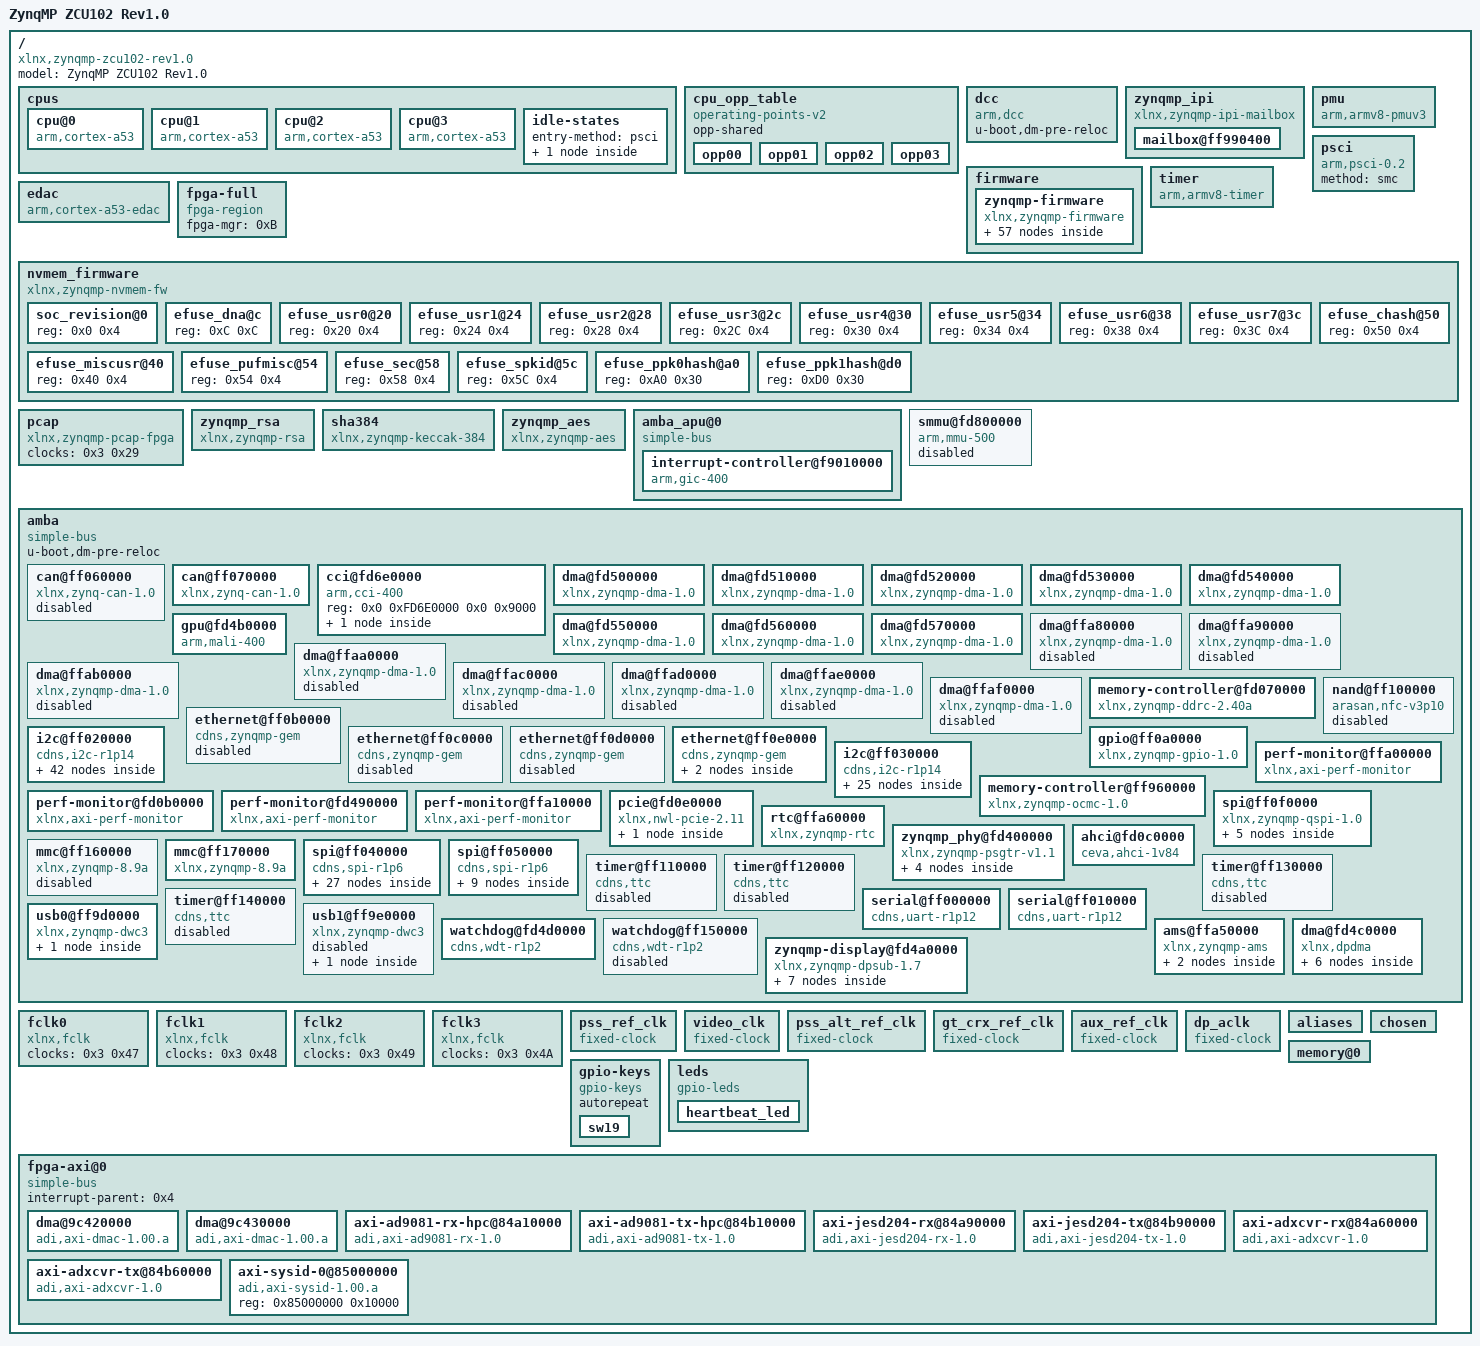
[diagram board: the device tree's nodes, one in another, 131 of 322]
/dts-v1/;
// version: 17
// last_comp_version: 16
// boot_cpuid_phys: 0x0

/ {
    compatible = "xlnx,zynqmp-zcu102-rev1.0", "xlnx,zynqmp-zcu102", "xlnx,zynqmp";
    #address-cells = <0x2>;
    #size-cells = <0x2>;
    model = "ZynqMP ZCU102 Rev1.0";
    cpus {
        #address-cells = <0x1>;
        #size-cells = <0x0>;
        cpu@0 {
            compatible = "arm,cortex-a53", "arm,armv8";
            device_type = "cpu";
            enable-method = "psci";
            operating-points-v2 = <0x1>;
            reg = <0x0>;
            cpu-idle-states = <0x2>;
            clocks = <0x3 0xA>;
        };
        cpu@1 {
            compatible = "arm,cortex-a53", "arm,armv8";
            device_type = "cpu";
            enable-method = "psci";
            reg = <0x1>;
            operating-points-v2 = <0x1>;
            cpu-idle-states = <0x2>;
        };
        cpu@2 {
            compatible = "arm,cortex-a53", "arm,armv8";
            device_type = "cpu";
            enable-method = "psci";
            reg = <0x2>;
            operating-points-v2 = <0x1>;
            cpu-idle-states = <0x2>;
        };
        cpu@3 {
            compatible = "arm,cortex-a53", "arm,armv8";
            device_type = "cpu";
            enable-method = "psci";
            reg = <0x3>;
            operating-points-v2 = <0x1>;
            cpu-idle-states = <0x2>;
        };
        idle-states {
            entry-method = "psci";
            cpu-sleep-0 {
                compatible = "arm,idle-state";
                arm,psci-suspend-param = <0x40000000>;
                local-timer-stop;
                entry-latency-us = <0x12C>;
                exit-latency-us = <0x258>;
                min-residency-us = <0x2710>;
                phandle = <0x2>;
            };
        };
    };
    cpu_opp_table {
        compatible = "operating-points-v2";
        opp-shared;
        phandle = <0x1>;
        opp00 {
            opp-hz = <0x0 0x47868BF4>;
            opp-microvolt = <0xF4240>;
            clock-latency-ns = <0x7A120>;
        };
        opp01 {
            opp-hz = <0x0 0x23C345FA>;
            opp-microvolt = <0xF4240>;
            clock-latency-ns = <0x7A120>;
        };
        opp02 {
            opp-hz = <0x0 0x17D783FC>;
            opp-microvolt = <0xF4240>;
            clock-latency-ns = <0x7A120>;
        };
        opp03 {
            opp-hz = <0x0 0x11E1A2FD>;
            opp-microvolt = <0xF4240>;
            clock-latency-ns = <0x7A120>;
        };
    };
    dcc {
        compatible = "arm,dcc";
        status = "okay";
        u-boot,dm-pre-reloc;
    };
    zynqmp_ipi {
        compatible = "xlnx,zynqmp-ipi-mailbox";
        interrupt-parent = <0x4>;
        interrupts = <0x0 0x23 0x4>;
        xlnx,ipi-id = <0x0>;
        #address-cells = <0x2>;
        #size-cells = <0x2>;
        ranges;
        mailbox@ff990400 {
            reg = <0x0 0xFF9905C0 0x0 0x20 0x0 0xFF9905E0 0x0 0x20 0x0 0xFF990E80 0x0 0x20 0x0 0xFF990EA0 0x0 0x20>;
            reg-names = "local_request_region", "local_response_region", "remote_request_region", "remote_response_region";
            #mbox-cells = <0x1>;
            xlnx,ipi-id = <0x4>;
            phandle = <0x5>;
        };
    };
    pmu {
        compatible = "arm,armv8-pmuv3";
        interrupt-parent = <0x4>;
        interrupts = <0x0 0x8F 0x4 0x0 0x90 0x4 0x0 0x91 0x4 0x0 0x92 0x4>;
    };
    psci {
        compatible = "arm,psci-0.2";
        method = "smc";
    };
    firmware {
        zynqmp-firmware {
            compatible = "xlnx,zynqmp-firmware";
            method = "smc";
            #power-domain-cells = <0x1>;
            u-boot,dm-pre-reloc;
            phandle = <0xC>;
            zynqmp-power {
                compatible = "xlnx,zynqmp-power";
                interrupt-parent = <0x4>;
                interrupts = <0x0 0x23 0x4>;
                mboxes = <0x5 0x0 0x5 0x1>;
                mbox-names = "tx", "rx";
            };
            reset-controller {
                compatible = "xlnx,zynqmp-reset";
                #reset-cells = <0x1>;
                phandle = <0x1A>;
            };
            pinctrl {
                compatible = "xlnx,zynqmp-pinctrl";
                status = "okay";
                i2c0-default {
                    phandle = <0x12>;
                    mux {
                        groups = "i2c0_3_grp";
                        function = "i2c0";
                    };
                    conf {
                        groups = "i2c0_3_grp";
                        bias-pull-up;
                        slew-rate = <0x1>;
                        io-standard = <0x1>;
                    };
                };
                i2c0-gpio {
                    phandle = <0x13>;
                    mux {
                        groups = "gpio0_14_grp", "gpio0_15_grp";
                        function = "gpio0";
                    };
                    conf {
                        groups = "gpio0_14_grp", "gpio0_15_grp";
                        slew-rate = <0x1>;
                        io-standard = <0x1>;
                    };
                };
                i2c1-default {
                    phandle = <0x15>;
                    mux {
                        groups = "i2c1_4_grp";
                        function = "i2c1";
                    };
                    conf {
                        groups = "i2c1_4_grp";
                        bias-pull-up;
                        slew-rate = <0x1>;
                        io-standard = <0x1>;
                    };
                };
                i2c1-gpio {
                    phandle = <0x16>;
                    mux {
                        groups = "gpio0_16_grp", "gpio0_17_grp";
                        function = "gpio0";
                    };
                    conf {
                        groups = "gpio0_16_grp", "gpio0_17_grp";
                        slew-rate = <0x1>;
                        io-standard = <0x1>;
                    };
                };
                uart0-default {
                    phandle = <0x28>;
                    mux {
                        groups = "uart0_4_grp";
                        function = "uart0";
                    };
                    conf {
                        groups = "uart0_4_grp";
                        slew-rate = <0x1>;
                        io-standard = <0x1>;
                    };
                    conf-rx {
                        pins = "MIO18";
                        bias-high-impedance;
                    };
                    conf-tx {
                        pins = "MIO19";
                        bias-disable;
                    };
                };
                uart1-default {
                    phandle = <0x29>;
                    mux {
                        groups = "uart1_5_grp";
                        function = "uart1";
                    };
                    conf {
                        groups = "uart1_5_grp";
                        slew-rate = <0x1>;
                        io-standard = <0x1>;
                    };
                    conf-rx {
                        pins = "MIO21";
                        bias-high-impedance;
                    };
                    conf-tx {
                        pins = "MIO20";
                        bias-disable;
                    };
                };
                usb0-default {
                    phandle = <0x2A>;
                    mux {
                        groups = "usb0_0_grp";
                        function = "usb0";
                    };
                    conf {
                        groups = "usb0_0_grp";
                        slew-rate = <0x1>;
                        io-standard = <0x1>;
                    };
                    conf-rx {
                        pins = "MIO52", "MIO53", "MIO55";
                        bias-high-impedance;
                    };
                    conf-tx {
                        pins = "MIO54", "MIO56", "MIO57", "MIO58", "MIO59", "MIO60", "MIO61", "MIO62", "MIO63";
                        bias-disable;
                    };
                };
                gem3-default {
                    phandle = <0x10>;
                    mux {
                        function = "ethernet3";
                        groups = "ethernet3_0_grp";
                    };
                    conf {
                        groups = "ethernet3_0_grp";
                        slew-rate = <0x1>;
                        io-standard = <0x1>;
                    };
                    conf-rx {
                        pins = "MIO70", "MIO71", "MIO72", "MIO73", "MIO74", "MIO75";
                        bias-high-impedance;
                        low-power-disable;
                    };
                    conf-tx {
                        pins = "MIO64", "MIO65", "MIO66", "MIO67", "MIO68", "MIO69";
                        bias-disable;
                        low-power-enable;
                    };
                    mux-mdio {
                        function = "mdio3";
                        groups = "mdio3_0_grp";
                    };
                    conf-mdio {
                        groups = "mdio3_0_grp";
                        slew-rate = <0x1>;
                        io-standard = <0x1>;
                        bias-disable;
                    };
                };
                can1-default {
                    phandle = <0xD>;
                    mux {
                        function = "can1";
                        groups = "can1_6_grp";
                    };
                    conf {
                        groups = "can1_6_grp";
                        slew-rate = <0x1>;
                        io-standard = <0x1>;
                    };
                    conf-rx {
                        pins = "MIO25";
                        bias-high-impedance;
                    };
                    conf-tx {
                        pins = "MIO24";
                        bias-disable;
                    };
                };
                sdhci1-default {
                    phandle = <0x1C>;
                    mux {
                        groups = "sdio1_0_grp";
                        function = "sdio1";
                    };
                    conf {
                        groups = "sdio1_0_grp";
                        slew-rate = <0x1>;
                        io-standard = <0x1>;
                        bias-disable;
                    };
                    mux-cd {
                        groups = "sdio1_cd_0_grp";
                        function = "sdio1_cd";
                    };
                    conf-cd {
                        groups = "sdio1_cd_0_grp";
                        bias-high-impedance;
                        bias-pull-up;
                        slew-rate = <0x1>;
                        io-standard = <0x1>;
                    };
                    mux-wp {
                        groups = "sdio1_wp_0_grp";
                        function = "sdio1_wp";
                    };
                    conf-wp {
                        groups = "sdio1_wp_0_grp";
                        bias-high-impedance;
                        bias-pull-up;
                        slew-rate = <0x1>;
                        io-standard = <0x1>;
                    };
                };
                gpio-default {
                    phandle = <0x11>;
                    mux-sw {
                        function = "gpio0";
                        groups = "gpio0_22_grp", "gpio0_23_grp";
                    };
                    conf-sw {
                        groups = "gpio0_22_grp", "gpio0_23_grp";
                        slew-rate = <0x1>;
                        io-standard = <0x1>;
                    };
                    mux-msp {
                        function = "gpio0";
                        groups = "gpio0_13_grp", "gpio0_38_grp";
                    };
                    conf-msp {
                        groups = "gpio0_13_grp", "gpio0_38_grp";
                        slew-rate = <0x1>;
                        io-standard = <0x1>;
                    };
                    conf-pull-up {
                        pins = "MIO22", "MIO23";
                        bias-pull-up;
                    };
                    conf-pull-none {
                        pins = "MIO13", "MIO38";
                        bias-disable;
                    };
                };
            };
            clock-controller {
                u-boot,dm-pre-reloc;
                #clock-cells = <0x1>;
                compatible = "xlnx,zynqmp-clk";
                clocks = <0x6 0x7 0x8 0x9 0xA>;
                clock-names = "pss_ref_clk", "video_clk", "pss_alt_ref_clk", "aux_ref_clk", "gt_crx_ref_clk";
                phandle = <0x3>;
            };
        };
    };
    timer {
        compatible = "arm,armv8-timer";
        interrupt-parent = <0x4>;
        interrupts = <0x1 0xD 0xF08 0x1 0xE 0xF08 0x1 0xB 0xF08 0x1 0xA 0xF08>;
    };
    edac {
        compatible = "arm,cortex-a53-edac";
    };
    fpga-full {
        compatible = "fpga-region";
        fpga-mgr = <0xB>;
        #address-cells = <0x2>;
        #size-cells = <0x2>;
    };
    nvmem_firmware {
        compatible = "xlnx,zynqmp-nvmem-fw";
        #address-cells = <0x1>;
        #size-cells = <0x1>;
        soc_revision@0 {
            reg = <0x0 0x4>;
            phandle = <0x19>;
        };
        efuse_dna@c {
            reg = <0xC 0xC>;
        };
        efuse_usr0@20 {
            reg = <0x20 0x4>;
        };
        efuse_usr1@24 {
            reg = <0x24 0x4>;
        };
        efuse_usr2@28 {
            reg = <0x28 0x4>;
        };
        efuse_usr3@2c {
            reg = <0x2C 0x4>;
        };
        efuse_usr4@30 {
            reg = <0x30 0x4>;
        };
        efuse_usr5@34 {
            reg = <0x34 0x4>;
        };
        efuse_usr6@38 {
            reg = <0x38 0x4>;
        };
        efuse_usr7@3c {
            reg = <0x3C 0x4>;
        };
        efuse_miscusr@40 {
            reg = <0x40 0x4>;
        };
        efuse_chash@50 {
            reg = <0x50 0x4>;
        };
        efuse_pufmisc@54 {
            reg = <0x54 0x4>;
        };
        efuse_sec@58 {
            reg = <0x58 0x4>;
        };
        efuse_spkid@5c {
            reg = <0x5C 0x4>;
        };
        efuse_ppk0hash@a0 {
            reg = <0xA0 0x30>;
        };
        efuse_ppk1hash@d0 {
            reg = <0xD0 0x30>;
        };
    };
    pcap {
        compatible = "xlnx,zynqmp-pcap-fpga";
        clock-names = "ref_clk";
        clocks = <0x3 0x29>;
        phandle = <0xB>;
    };
    zynqmp_rsa {
        compatible = "xlnx,zynqmp-rsa";
    };
    sha384 {
        compatible = "xlnx,zynqmp-keccak-384";
    };
    zynqmp_aes {
        compatible = "xlnx,zynqmp-aes";
    };
    amba_apu@0 {
        compatible = "simple-bus";
        #address-cells = <0x2>;
        #size-cells = <0x1>;
        ranges = <0x0 0x0 0x0 0x0 0xFFFFFFFF>;
        interrupt-controller@f9010000 {
            compatible = "arm,gic-400", "arm,cortex-a15-gic";
            #interrupt-cells = <0x3>;
            reg = <0x0 0xF9010000 0x10000 0x0 0xF9020000 0x20000 0x0 0xF9040000 0x20000 0x0 0xF9060000 0x20000>;
            interrupt-controller;
            interrupt-parent = <0x4>;
            interrupts = <0x1 0x9 0xF04>;
            phandle = <0x4>;
        };
    };
    smmu@fd800000 {
        compatible = "arm,mmu-500";
        reg = <0x0 0xFD800000 0x0 0x20000>;
        #iommu-cells = <0x1>;
        status = "disabled";
        #global-interrupts = <0x1>;
        interrupt-parent = <0x4>;
        interrupts = <0x0 0x9B 0x4 0x0 0x9B 0x4 0x0 0x9B 0x4 0x0 0x9B 0x4 0x0 0x9B 0x4 0x0 0x9B 0x4 0x0 0x9B 0x4 0x0 0x9B 0x4 0x0 0x9B 0x4 0x0 0x9B 0x4 0x0 0x9B 0x4 0x0 0x9B 0x4 0x0 0x9B 0x4 0x0 0x9B 0x4 0x0 0x9B 0x4 0x0 0x9B 0x4 0x0 0x9B 0x4>;
        phandle = <0xE>;
    };
    amba {
        compatible = "simple-bus";
        u-boot,dm-pre-reloc;
        #address-cells = <0x2>;
        #size-cells = <0x2>;
        ranges;
        can@ff060000 {
            compatible = "xlnx,zynq-can-1.0";
            status = "disabled";
            clock-names = "can_clk", "pclk";
            reg = <0x0 0xFF060000 0x0 0x1000>;
            interrupts = <0x0 0x17 0x4>;
            interrupt-parent = <0x4>;
            tx-fifo-depth = <0x40>;
            rx-fifo-depth = <0x40>;
            power-domains = <0xC 0x2F>;
            clocks = <0x3 0x3F 0x3 0x1F>;
        };
        can@ff070000 {
            compatible = "xlnx,zynq-can-1.0";
            status = "okay";
            clock-names = "can_clk", "pclk";
            reg = <0x0 0xFF070000 0x0 0x1000>;
            interrupts = <0x0 0x18 0x4>;
            interrupt-parent = <0x4>;
            tx-fifo-depth = <0x40>;
            rx-fifo-depth = <0x40>;
            power-domains = <0xC 0x30>;
            clocks = <0x3 0x40 0x3 0x1F>;
            pinctrl-names = "default";
            pinctrl-0 = <0xD>;
        };
        cci@fd6e0000 {
            compatible = "arm,cci-400";
            reg = <0x0 0xFD6E0000 0x0 0x9000>;
            ranges = <0x0 0x0 0xFD6E0000 0x10000>;
            #address-cells = <0x1>;
            #size-cells = <0x1>;
            pmu@9000 {
                compatible = "arm,cci-400-pmu,r1";
                reg = <0x9000 0x5000>;
                interrupt-parent = <0x4>;
                interrupts = <0x0 0x7B 0x4 0x0 0x7B 0x4 0x0 0x7B 0x4 0x0 0x7B 0x4 0x0 0x7B 0x4>;
            };
        };
        dma@fd500000 {
            status = "okay";
            compatible = "xlnx,zynqmp-dma-1.0";
            reg = <0x0 0xFD500000 0x0 0x1000>;
            interrupt-parent = <0x4>;
            interrupts = <0x0 0x7C 0x4>;
            clock-names = "clk_main", "clk_apb";
            xlnx,bus-width = <0x80>;
            #stream-id-cells = <0x1>;
            iommus = <0xE 0x14E8>;
            power-domains = <0xC 0x2A>;
            clocks = <0x3 0x13 0x3 0x1F>;
        };
        dma@fd510000 {
            status = "okay";
            compatible = "xlnx,zynqmp-dma-1.0";
            reg = <0x0 0xFD510000 0x0 0x1000>;
            interrupt-parent = <0x4>;
            interrupts = <0x0 0x7D 0x4>;
            clock-names = "clk_main", "clk_apb";
            xlnx,bus-width = <0x80>;
            #stream-id-cells = <0x1>;
            iommus = <0xE 0x14E9>;
            power-domains = <0xC 0x2A>;
            clocks = <0x3 0x13 0x3 0x1F>;
        };
        dma@fd520000 {
            status = "okay";
            compatible = "xlnx,zynqmp-dma-1.0";
            reg = <0x0 0xFD520000 0x0 0x1000>;
            interrupt-parent = <0x4>;
            interrupts = <0x0 0x7E 0x4>;
            clock-names = "clk_main", "clk_apb";
            xlnx,bus-width = <0x80>;
            #stream-id-cells = <0x1>;
            iommus = <0xE 0x14EA>;
            power-domains = <0xC 0x2A>;
            clocks = <0x3 0x13 0x3 0x1F>;
        };
        dma@fd530000 {
            status = "okay";
            compatible = "xlnx,zynqmp-dma-1.0";
            reg = <0x0 0xFD530000 0x0 0x1000>;
            interrupt-parent = <0x4>;
            interrupts = <0x0 0x7F 0x4>;
            clock-names = "clk_main", "clk_apb";
            xlnx,bus-width = <0x80>;
            #stream-id-cells = <0x1>;
            iommus = <0xE 0x14EB>;
            power-domains = <0xC 0x2A>;
            clocks = <0x3 0x13 0x3 0x1F>;
        };
        dma@fd540000 {
            status = "okay";
            compatible = "xlnx,zynqmp-dma-1.0";
            reg = <0x0 0xFD540000 0x0 0x1000>;
            interrupt-parent = <0x4>;
            interrupts = <0x0 0x80 0x4>;
            clock-names = "clk_main", "clk_apb";
            xlnx,bus-width = <0x80>;
            #stream-id-cells = <0x1>;
            iommus = <0xE 0x14EC>;
            power-domains = <0xC 0x2A>;
            clocks = <0x3 0x13 0x3 0x1F>;
        };
        dma@fd550000 {
            status = "okay";
            compatible = "xlnx,zynqmp-dma-1.0";
            reg = <0x0 0xFD550000 0x0 0x1000>;
            interrupt-parent = <0x4>;
            interrupts = <0x0 0x81 0x4>;
            clock-names = "clk_main", "clk_apb";
            xlnx,bus-width = <0x80>;
            #stream-id-cells = <0x1>;
            iommus = <0xE 0x14ED>;
            power-domains = <0xC 0x2A>;
            clocks = <0x3 0x13 0x3 0x1F>;
        };
        dma@fd560000 {
            status = "okay";
            compatible = "xlnx,zynqmp-dma-1.0";
            reg = <0x0 0xFD560000 0x0 0x1000>;
            interrupt-parent = <0x4>;
            interrupts = <0x0 0x82 0x4>;
            clock-names = "clk_main", "clk_apb";
            xlnx,bus-width = <0x80>;
            #stream-id-cells = <0x1>;
            iommus = <0xE 0x14EE>;
            power-domains = <0xC 0x2A>;
            clocks = <0x3 0x13 0x3 0x1F>;
        };
        dma@fd570000 {
            status = "okay";
            compatible = "xlnx,zynqmp-dma-1.0";
            reg = <0x0 0xFD570000 0x0 0x1000>;
            interrupt-parent = <0x4>;
            interrupts = <0x0 0x83 0x4>;
            clock-names = "clk_main", "clk_apb";
            xlnx,bus-width = <0x80>;
            #stream-id-cells = <0x1>;
            iommus = <0xE 0x14EF>;
            power-domains = <0xC 0x2A>;
            clocks = <0x3 0x13 0x3 0x1F>;
        };
        gpu@fd4b0000 {
            status = "okay";
            compatible = "arm,mali-400", "arm,mali-utgard";
            reg = <0x0 0xFD4B0000 0x0 0x10000>;
            interrupt-parent = <0x4>;
            interrupts = <0x0 0x84 0x4 0x0 0x84 0x4 0x0 0x84 0x4 0x0 0x84 0x4 0x0 0x84 0x4 0x0 0x84 0x4>;
            interrupt-names = "IRQGP", "IRQGPMMU", "IRQPP0", "IRQPPMMU0", "IRQPP1", "IRQPPMMU1";
            clock-names = "gpu", "gpu_pp0", "gpu_pp1";
            power-domains = <0xC 0x3A>;
            clocks = <0x3 0x18 0x3 0x19 0x3 0x1A>;
        };
        dma@ffa80000 {
            status = "disabled";
            compatible = "xlnx,zynqmp-dma-1.0";
            reg = <0x0 0xFFA80000 0x0 0x1000>;
            interrupt-parent = <0x4>;
            interrupts = <0x0 0x4D 0x4>;
            clock-names = "clk_main", "clk_apb";
            xlnx,bus-width = <0x40>;
            #stream-id-cells = <0x1>;
            power-domains = <0xC 0x2B>;
            clocks = <0x3 0x44 0x3 0x1F>;
        };
        dma@ffa90000 {
            status = "disabled";
            compatible = "xlnx,zynqmp-dma-1.0";
            reg = <0x0 0xFFA90000 0x0 0x1000>;
            interrupt-parent = <0x4>;
            interrupts = <0x0 0x4E 0x4>;
            clock-names = "clk_main", "clk_apb";
            xlnx,bus-width = <0x40>;
            #stream-id-cells = <0x1>;
            power-domains = <0xC 0x2B>;
            clocks = <0x3 0x44 0x3 0x1F>;
        };
        dma@ffaa0000 {
            status = "disabled";
            compatible = "xlnx,zynqmp-dma-1.0";
            reg = <0x0 0xFFAA0000 0x0 0x1000>;
            interrupt-parent = <0x4>;
            interrupts = <0x0 0x4F 0x4>;
            clock-names = "clk_main", "clk_apb";
            xlnx,bus-width = <0x40>;
            #stream-id-cells = <0x1>;
            power-domains = <0xC 0x2B>;
            clocks = <0x3 0x44 0x3 0x1F>;
        };
        dma@ffab0000 {
            status = "disabled";
            compatible = "xlnx,zynqmp-dma-1.0";
            reg = <0x0 0xFFAB0000 0x0 0x1000>;
            interrupt-parent = <0x4>;
            interrupts = <0x0 0x50 0x4>;
            clock-names = "clk_main", "clk_apb";
            xlnx,bus-width = <0x40>;
            #stream-id-cells = <0x1>;
            power-domains = <0xC 0x2B>;
            clocks = <0x3 0x44 0x3 0x1F>;
        };
        dma@ffac0000 {
            status = "disabled";
            compatible = "xlnx,zynqmp-dma-1.0";
            reg = <0x0 0xFFAC0000 0x0 0x1000>;
            interrupt-parent = <0x4>;
            interrupts = <0x0 0x51 0x4>;
            clock-names = "clk_main", "clk_apb";
            xlnx,bus-width = <0x40>;
            #stream-id-cells = <0x1>;
            power-domains = <0xC 0x2B>;
            clocks = <0x3 0x44 0x3 0x1F>;
        };
        dma@ffad0000 {
            status = "disabled";
            compatible = "xlnx,zynqmp-dma-1.0";
            reg = <0x0 0xFFAD0000 0x0 0x1000>;
            interrupt-parent = <0x4>;
            interrupts = <0x0 0x52 0x4>;
            clock-names = "clk_main", "clk_apb";
            xlnx,bus-width = <0x40>;
            #stream-id-cells = <0x1>;
            power-domains = <0xC 0x2B>;
            clocks = <0x3 0x44 0x3 0x1F>;
        };
        dma@ffae0000 {
            status = "disabled";
            compatible = "xlnx,zynqmp-dma-1.0";
            reg = <0x0 0xFFAE0000 0x0 0x1000>;
            interrupt-parent = <0x4>;
            interrupts = <0x0 0x53 0x4>;
            clock-names = "clk_main", "clk_apb";
            xlnx,bus-width = <0x40>;
            #stream-id-cells = <0x1>;
            power-domains = <0xC 0x2B>;
            clocks = <0x3 0x44 0x3 0x1F>;
        };
        dma@ffaf0000 {
            status = "disabled";
            compatible = "xlnx,zynqmp-dma-1.0";
            reg = <0x0 0xFFAF0000 0x0 0x1000>;
            interrupt-parent = <0x4>;
            interrupts = <0x0 0x54 0x4>;
            clock-names = "clk_main", "clk_apb";
            xlnx,bus-width = <0x40>;
            #stream-id-cells = <0x1>;
            power-domains = <0xC 0x2B>;
            clocks = <0x3 0x44 0x3 0x1F>;
        };
        memory-controller@fd070000 {
            compatible = "xlnx,zynqmp-ddrc-2.40a";
            reg = <0x0 0xFD070000 0x0 0x30000>;
            interrupt-parent = <0x4>;
            interrupts = <0x0 0x70 0x4>;
        };
        nand@ff100000 {
            compatible = "arasan,nfc-v3p10";
            status = "disabled";
            reg = <0x0 0xFF100000 0x0 0x1000>;
            clock-names = "clk_sys", "clk_flash";
            interrupt-parent = <0x4>;
            interrupts = <0x0 0xE 0x4>;
            #address-cells = <0x1>;
            #size-cells = <0x0>;
            #stream-id-cells = <0x1>;
            iommus = <0xE 0x872>;
            power-domains = <0xC 0x2C>;
            clocks = <0x3 0x3C 0x3 0x1F>;
        };
        ethernet@ff0b0000 {
            compatible = "cdns,zynqmp-gem", "cdns,gem";
            status = "disabled";
            interrupt-parent = <0x4>;
            interrupts = <0x0 0x39 0x4 0x0 0x39 0x4>;
            reg = <0x0 0xFF0B0000 0x0 0x1000>;
            clock-names = "pclk", "hclk", "tx_clk", "rx_clk", "tsu_clk";
            #address-cells = <0x1>;
            #size-cells = <0x0>;
            #stream-id-cells = <0x1>;
            iommus = <0xE 0x874>;
            power-domains = <0xC 0x1D>;
            clocks = <0x3 0x1F 0x3 0x68 0x3 0x2D 0x3 0x31 0x3 0x2C>;
        };
        ethernet@ff0c0000 {
            compatible = "cdns,zynqmp-gem", "cdns,gem";
            status = "disabled";
            interrupt-parent = <0x4>;
            interrupts = <0x0 0x3B 0x4 0x0 0x3B 0x4>;
            reg = <0x0 0xFF0C0000 0x0 0x1000>;
            clock-names = "pclk", "hclk", "tx_clk", "rx_clk", "tsu_clk";
            #address-cells = <0x1>;
            #size-cells = <0x0>;
            #stream-id-cells = <0x1>;
            iommus = <0xE 0x875>;
            power-domains = <0xC 0x1E>;
            clocks = <0x3 0x1F 0x3 0x69 0x3 0x2E 0x3 0x32 0x3 0x2C>;
        };
        ethernet@ff0d0000 {
            compatible = "cdns,zynqmp-gem", "cdns,gem";
            status = "disabled";
            interrupt-parent = <0x4>;
            interrupts = <0x0 0x3D 0x4 0x0 0x3D 0x4>;
            reg = <0x0 0xFF0D0000 0x0 0x1000>;
            clock-names = "pclk", "hclk", "tx_clk", "rx_clk", "tsu_clk";
            #address-cells = <0x1>;
            #size-cells = <0x0>;
            #stream-id-cells = <0x1>;
            iommus = <0xE 0x876>;
            power-domains = <0xC 0x1F>;
            clocks = <0x3 0x1F 0x3 0x6A 0x3 0x2F 0x3 0x33 0x3 0x2C>;
        };
        ethernet@ff0e0000 {
            compatible = "cdns,zynqmp-gem", "cdns,gem";
            status = "okay";
            interrupt-parent = <0x4>;
            interrupts = <0x0 0x3F 0x4 0x0 0x3F 0x4>;
            reg = <0x0 0xFF0E0000 0x0 0x1000>;
            clock-names = "pclk", "hclk", "tx_clk", "rx_clk", "tsu_clk";
            #address-cells = <0x1>;
            #size-cells = <0x0>;
            #stream-id-cells = <0x1>;
            iommus = <0xE 0x877>;
            power-domains = <0xC 0x20>;
            clocks = <0x3 0x1F 0x3 0x6B 0x3 0x30 0x3 0x34 0x3 0x2C>;
            phy-handle = <0xF>;
            phy-mode = "rgmii-id";
            pinctrl-names = "default";
            pinctrl-0 = <0x10>;
            ethernet-phy@21 {
                reg = <0x15>;
                ti,rx-internal-delay = <0x8>;
                ti,tx-internal-delay = <0xA>;
                ti,fifo-depth = <0x1>;
                ti,dp83867-rxctrl-strap-quirk;
            };
            ethernet-phy@c {
                reg = <0xC>;
                ti,rx-internal-delay = <0x8>;
                ti,tx-internal-delay = <0xA>;
                ti,fifo-depth = <0x1>;
                ti,dp83867-rxctrl-strap-quirk;
                phandle = <0xF>;
            };
        };
        gpio@ff0a0000 {
            compatible = "xlnx,zynqmp-gpio-1.0";
            status = "okay";
            #gpio-cells = <0x2>;
            interrupt-parent = <0x4>;
            interrupts = <0x0 0x10 0x4>;
            interrupt-controller;
            #interrupt-cells = <0x2>;
            reg = <0x0 0xFF0A0000 0x0 0x1000>;
            gpio-controller;
            power-domains = <0xC 0x2E>;
            clocks = <0x3 0x1F>;
            pinctrl-names = "default";
            pinctrl-0 = <0x11>;
            phandle = <0x14>;
        };
        i2c@ff020000 {
            compatible = "cdns,i2c-r1p14", "cdns,i2c-r1p10";
            status = "okay";
            interrupt-parent = <0x4>;
            interrupts = <0x0 0x11 0x4>;
            reg = <0x0 0xFF020000 0x0 0x1000>;
            #address-cells = <0x1>;
            #size-cells = <0x0>;
            power-domains = <0xC 0x25>;
            clocks = <0x3 0x3D>;
            clock-frequency = <0x61A80>;
            pinctrl-names = "default", "gpio";
            pinctrl-0 = <0x12>;
            pinctrl-1 = <0x13>;
            scl-gpios = <0x14 0xE 0x0>;
            sda-gpios = <0x14 0xF 0x0>;
            gpio@20 {
                compatible = "ti,tca6416";
                reg = <0x20>;
                gpio-controller;
                #gpio-cells = <0x2>;
                gpio-line-names = [50 53 5F 47 54 52 5F 4C 41 4E 5F 53 45 4C 30 00 50 53 5F 47 54 52 5F 4C 41 4E 5F 53 45 4C 31 00 50 53 5F 47 54 52 5F 4C 41 4E 5F 53 45 4C 32 00 50 53 5F 47 54 52 5F 4C 41 4E 5F 53 45 4C 33 00 50 43 49 5F 43 4C 4B 5F 44 49 52 5F 53 45 4C 00 49 49 43 5F 4D 55 58 5F 52 45 53 45 54 5F 42 00 47 45 4D 33 5F 45 58 50 5F 52 45 53 45 54 5F 42 00 00 00 00 00 00 00 00 00 00];
                gtr_sel0 {
                    gpio-hog;
                    gpios = <0x0 0x0>;
                    output-low;
                    line-name = "sel0";
                };
                gtr_sel1 {
                    gpio-hog;
                    gpios = <0x1 0x0>;
                    output-high;
                    line-name = "sel1";
                };
                gtr_sel2 {
                    gpio-hog;
                    gpios = <0x2 0x0>;
                    output-high;
                    line-name = "sel2";
                };
                gtr_sel3 {
                    gpio-hog;
                    gpios = <0x3 0x0>;
                    output-high;
                    line-name = "sel3";
                };
            };
            gpio@21 {
                compatible = "ti,tca6416";
                reg = <0x21>;
                gpio-controller;
                #gpio-cells = <0x2>;
                gpio-line-names = [56 43 43 50 53 50 4C 4C 5F 45 4E 00 4D 47 54 52 41 56 43 43 5F 45 4E 00 4D 47 54 52 41 56 54 54 5F 45 4E 00 56 43 43 50 53 44 44 52 50 4C 4C 5F 45 4E 00 4D 49 4F 32 36 5F 50 4D 55 5F 49 4E 50 55 54 5F 4C 53 00 50 4C 5F 50 4D 42 55 53 5F 41 4C 45 52 54 00 50 53 5F 50 4D 42 55 53 5F 41 4C 45 52 54 00 4D 41 58 49 4D 5F 50 4D 42 55 53 5F 41 4C 45 52 54 00 50 4C 5F 44 44 52 34 5F 56 54 45 52 4D 5F 45 4E 00 50 4C 5F 44 44 52 34 5F 56 50 50 5F 32 56 35 5F 45 4E 00 50 53 5F 44 49 4D 4D 5F 56 44 44 51 5F 54 4F 5F 50 53 56 43 43 4F 5F 4F 4E 00 50 53 5F 44 49 4D 4D 5F 53 55 53 50 45 4E 44 5F 45 4E 00 50 53 5F 44 44 52 34 5F 56 54 45 52 4D 5F 45 4E 00 50 53 5F 44 44 52 34 5F 56 50 50 5F 32 56 35 5F 45 4E 00 00 00];
            };
            i2c-mux@75 {
                compatible = "nxp,pca9544";
                #address-cells = <0x1>;
                #size-cells = <0x0>;
                reg = <0x75>;
                i2c@0 {
                    #address-cells = <0x1>;
                    #size-cells = <0x0>;
                    reg = <0x0>;
                    ina226@40 {
                        compatible = "ti,ina226";
                        reg = <0x40>;
                        shunt-resistor = <0x1388>;
                    };
                    ina226@41 {
                        compatible = "ti,ina226";
                        reg = <0x41>;
                        shunt-resistor = <0x1388>;
                    };
                    ina226@42 {
                        compatible = "ti,ina226";
                        reg = <0x42>;
                        shunt-resistor = <0x1388>;
                    };
                    ina226@43 {
                        compatible = "ti,ina226";
                        reg = <0x43>;
                        shunt-resistor = <0x1388>;
                    };
                    ina226@44 {
                        compatible = "ti,ina226";
                        reg = <0x44>;
                        shunt-resistor = <0x1388>;
                    };
                    ina226@45 {
                        compatible = "ti,ina226";
                        reg = <0x45>;
                        shunt-resistor = <0x1388>;
                    };
                    ina226@46 {
                        compatible = "ti,ina226";
                        reg = <0x46>;
                        shunt-resistor = <0x1388>;
                    };
                    ina226@47 {
                        compatible = "ti,ina226";
                        reg = <0x47>;
                        shunt-resistor = <0x1388>;
                    };
                    ina226@4a {
                        compatible = "ti,ina226";
                        reg = <0x4A>;
                        shunt-resistor = <0x1388>;
                    };
                    ina226@4b {
                        compatible = "ti,ina226";
                        reg = <0x4B>;
                        shunt-resistor = <0x1388>;
                    };
                };
                i2c@1 {
                    #address-cells = <0x1>;
                    #size-cells = <0x0>;
                    reg = <0x1>;
                    ina226@40 {
                        compatible = "ti,ina226";
                        reg = <0x40>;
                        shunt-resistor = <0x7D0>;
                    };
                    ina226@41 {
                        compatible = "ti,ina226";
                        reg = <0x41>;
                        shunt-resistor = <0x1388>;
                    };
                    ina226@42 {
                        compatible = "ti,ina226";
                        reg = <0x42>;
                        shunt-resistor = <0x1388>;
                    };
                    ina226@43 {
                        compatible = "ti,ina226";
                        reg = <0x43>;
                        shunt-resistor = <0x1388>;
                    };
                    ina226@44 {
                        compatible = "ti,ina226";
                        reg = <0x44>;
                        shunt-resistor = <0x1388>;
                    };
                    ina226@45 {
                        compatible = "ti,ina226";
                        reg = <0x45>;
                        shunt-resistor = <0x1388>;
                    };
                    ina226@46 {
                        compatible = "ti,ina226";
                        reg = <0x46>;
                        shunt-resistor = <0x1388>;
                    };
                    ina226@47 {
                        compatible = "ti,ina226";
                        reg = <0x47>;
                        shunt-resistor = <0x1388>;
                    };
                };
                i2c@2 {
                    #address-cells = <0x1>;
                    #size-cells = <0x0>;
                    reg = <0x2>;
                    max15301@a {
                        compatible = "maxim,max15301";
                        reg = <0xA>;
                    };
                    max15303@b {
                        compatible = "maxim,max15303";
                        reg = <0xB>;
                    };
                    max15303@10 {
                        compatible = "maxim,max15303";
                        reg = <0x10>;
                    };
                    max15301@13 {
                        compatible = "maxim,max15301";
                        reg = <0x13>;
                    };
                    max15303@14 {
                        compatible = "maxim,max15303";
                        reg = <0x14>;
                    };
                    max15303@15 {
                        compatible = "maxim,max15303";
                        reg = <0x15>;
                    };
                    max15303@16 {
                        compatible = "maxim,max15303";
                        reg = <0x16>;
                    };
                    max15303@17 {
                        compatible = "maxim,max15303";
                        reg = <0x17>;
                    };
                    max15301@18 {
                        compatible = "maxim,max15301";
                        reg = <0x18>;
                    };
                    max15303@1a {
                        compatible = "maxim,max15303";
                        reg = <0x1A>;
                    };
                    max15303@1d {
                        compatible = "maxim,max15303";
                        reg = <0x1D>;
                    };
                    max20751@72 {
                        compatible = "maxim,max20751";
                        reg = <0x72>;
                    };
                    max20751@73 {
                        compatible = "maxim,max20751";
                        reg = <0x73>;
                    };
                    max15303@1b {
                        compatible = "maxim,max15303";
                        reg = <0x1B>;
                    };
                };
            };
        };
        i2c@ff030000 {
            compatible = "cdns,i2c-r1p14", "cdns,i2c-r1p10";
            status = "okay";
            interrupt-parent = <0x4>;
            interrupts = <0x0 0x12 0x4>;
            reg = <0x0 0xFF030000 0x0 0x1000>;
            #address-cells = <0x1>;
            #size-cells = <0x0>;
            power-domains = <0xC 0x26>;
            clocks = <0x3 0x3E>;
            clock-frequency = <0x61A80>;
            pinctrl-names = "default", "gpio";
            pinctrl-0 = <0x15>;
            pinctrl-1 = <0x16>;
            scl-gpios = <0x14 0x10 0x0>;
            sda-gpios = <0x14 0x11 0x0>;
            i2c-mux@74 {
                compatible = "nxp,pca9548";
                #address-cells = <0x1>;
                #size-cells = <0x0>;
                reg = <0x74>;
                i2c@0 {
                    #address-cells = <0x1>;
                    #size-cells = <0x0>;
                    reg = <0x0>;
                    eeprom@54 {
                        compatible = "atmel,24c08";
                        reg = <0x54>;
                        #address-cells = <0x1>;
                        #size-cells = <0x1>;
                        board-sn@0 {
                            reg = <0x0 0x14>;
                        };
                        eth-mac@20 {
                            reg = <0x20 0x6>;
                        };
                        board-name@d0 {
                            reg = <0xD0 0x6>;
                        };
                        board-revision@e0 {
                            reg = <0xE0 0x3>;
                        };
                    };
                };
                i2c@1 {
                    #address-cells = <0x1>;
                    #size-cells = <0x0>;
                    reg = <0x1>;
                    clock-generator@36 {
                        compatible = "silabs,si5341";
                        reg = <0x36>;
                    };
                };
                i2c@2 {
                    #address-cells = <0x1>;
                    #size-cells = <0x0>;
                    reg = <0x2>;
                    clock-generator@5d {
                        #clock-cells = <0x0>;
                        compatible = "silabs,si570";
                        reg = <0x5D>;
                        temperature-stability = <0x32>;
                        factory-fout = <0x11E1A300>;
                        clock-frequency = <0x11E1A300>;
                        clock-output-names = "si570_user";
                    };
                };
                i2c@3 {
                    #address-cells = <0x1>;
                    #size-cells = <0x0>;
                    reg = <0x3>;
                    clock-generator@5d {
                        #clock-cells = <0x0>;
                        compatible = "silabs,si570";
                        reg = <0x5D>;
                        temperature-stability = <0x32>;
                        factory-fout = <0x9502F90>;
                        clock-frequency = <0x8D9EE20>;
                        clock-output-names = "si570_mgt";
                    };
                };
                i2c@4 {
                    #address-cells = <0x1>;
                    #size-cells = <0x0>;
                    reg = <0x4>;
                    clock-generator@69 {
                        compatible = "silabs,si5328";
                        reg = <0x69>;
                    };
                };
            };
            i2c-mux@75 {
                compatible = "nxp,pca9548";
                #address-cells = <0x1>;
                #size-cells = <0x0>;
                reg = <0x75>;
                i2c@0 {
                    #address-cells = <0x1>;
                    #size-cells = <0x0>;
                    reg = <0x0>;
                    eeprom@50 {
                        compatible = "at24,24c02";
                        reg = <0x50>;
                    };
                };
                i2c@1 {
                    #address-cells = <0x1>;
                    #size-cells = <0x0>;
                    reg = <0x1>;
                };
                i2c@2 {
                    #address-cells = <0x1>;
                    #size-cells = <0x0>;
                    reg = <0x2>;
                };
                i2c@3 {
                    #address-cells = <0x1>;
                    #size-cells = <0x0>;
                    reg = <0x3>;
                };
                i2c@4 {
                    #address-cells = <0x1>;
                    #size-cells = <0x0>;
                    reg = <0x4>;
                };
                i2c@5 {
                    #address-cells = <0x1>;
                    #size-cells = <0x0>;
                    reg = <0x5>;
                };
                i2c@6 {
                    #address-cells = <0x1>;
                    #size-cells = <0x0>;
                    reg = <0x6>;
                };
                i2c@7 {
                    #address-cells = <0x1>;
                    #size-cells = <0x0>;
                    reg = <0x7>;
                };
            };
        };
        memory-controller@ff960000 {
            compatible = "xlnx,zynqmp-ocmc-1.0";
            reg = <0x0 0xFF960000 0x0 0x1000>;
            interrupt-parent = <0x4>;
            interrupts = <0x0 0xA 0x4>;
        };
        perf-monitor@ffa00000 {
            compatible = "xlnx,axi-perf-monitor";
            reg = <0x0 0xFFA00000 0x0 0x10000>;
            interrupts = <0x0 0x19 0x4>;
            interrupt-parent = <0x4>;
            xlnx,enable-profile = <0x0>;
            xlnx,enable-trace = <0x0>;
            xlnx,num-monitor-slots = <0x1>;
            xlnx,enable-event-count = <0x1>;
            xlnx,enable-event-log = <0x1>;
            xlnx,have-sampled-metric-cnt = <0x1>;
            xlnx,num-of-counters = <0x8>;
            xlnx,metric-count-width = <0x20>;
            xlnx,metrics-sample-count-width = <0x20>;
            xlnx,global-count-width = <0x20>;
            xlnx,metric-count-scale = <0x1>;
            clocks = <0x3 0x1F>;
        };
        perf-monitor@fd0b0000 {
            compatible = "xlnx,axi-perf-monitor";
            reg = <0x0 0xFD0B0000 0x0 0x10000>;
            interrupts = <0x0 0x7B 0x4>;
            interrupt-parent = <0x4>;
            xlnx,enable-profile = <0x0>;
            xlnx,enable-trace = <0x0>;
            xlnx,num-monitor-slots = <0x6>;
            xlnx,enable-event-count = <0x1>;
            xlnx,enable-event-log = <0x0>;
            xlnx,have-sampled-metric-cnt = <0x1>;
            xlnx,num-of-counters = <0xA>;
            xlnx,metric-count-width = <0x20>;
            xlnx,metrics-sample-count-width = <0x20>;
            xlnx,global-count-width = <0x20>;
            xlnx,metric-count-scale = <0x1>;
            clocks = <0x3 0x1C>;
        };
        perf-monitor@fd490000 {
            compatible = "xlnx,axi-perf-monitor";
            reg = <0x0 0xFD490000 0x0 0x10000>;
            interrupts = <0x0 0x7B 0x4>;
            interrupt-parent = <0x4>;
            xlnx,enable-profile = <0x0>;
            xlnx,enable-trace = <0x0>;
            xlnx,num-monitor-slots = <0x1>;
            xlnx,enable-event-count = <0x1>;
            xlnx,enable-event-log = <0x0>;
            xlnx,have-sampled-metric-cnt = <0x1>;
            xlnx,num-of-counters = <0x8>;
            xlnx,metric-count-width = <0x20>;
            xlnx,metrics-sample-count-width = <0x20>;
            xlnx,global-count-width = <0x20>;
            xlnx,metric-count-scale = <0x1>;
            clocks = <0x3 0x1C>;
        };
        perf-monitor@ffa10000 {
            compatible = "xlnx,axi-perf-monitor";
            reg = <0x0 0xFFA10000 0x0 0x10000>;
            interrupts = <0x0 0x19 0x4>;
            interrupt-parent = <0x4>;
            xlnx,enable-profile = <0x0>;
            xlnx,enable-trace = <0x0>;
            xlnx,num-monitor-slots = <0x1>;
            xlnx,enable-event-count = <0x1>;
            xlnx,enable-event-log = <0x1>;
            xlnx,have-sampled-metric-cnt = <0x1>;
            xlnx,num-of-counters = <0x8>;
            xlnx,metric-count-width = <0x20>;
            xlnx,metrics-sample-count-width = <0x20>;
            xlnx,global-count-width = <0x20>;
            xlnx,metric-count-scale = <0x1>;
            clocks = <0x3 0x1F>;
        };
        pcie@fd0e0000 {
            compatible = "xlnx,nwl-pcie-2.11";
            status = "okay";
            #address-cells = <0x3>;
            #size-cells = <0x2>;
            #interrupt-cells = <0x1>;
            msi-controller;
            device_type = "pci";
            interrupt-parent = <0x4>;
            interrupts = <0x0 0x76 0x4 0x0 0x75 0x4 0x0 0x74 0x4 0x0 0x73 0x4 0x0 0x72 0x4>;
            interrupt-names = "misc", "dummy", "intx", "msi1", "msi0";
            msi-parent = <0x17>;
            reg = <0x0 0xFD0E0000 0x0 0x1000 0x0 0xFD480000 0x0 0x1000 0x80 0x0 0x0 0x1000000>;
            reg-names = "breg", "pcireg", "cfg";
            ranges = <0x2000000 0x0 0xE0000000 0x0 0xE0000000 0x0 0x10000000 0x43000000 0x6 0x0 0x6 0x0 0x2 0x0>;
            bus-range = <0x0 0xFF>;
            interrupt-map-mask = <0x0 0x0 0x0 0x7>;
            interrupt-map = <0x0 0x0 0x0 0x1 0x18 0x1 0x0 0x0 0x0 0x2 0x18 0x2 0x0 0x0 0x0 0x3 0x18 0x3 0x0 0x0 0x0 0x4 0x18 0x4>;
            power-domains = <0xC 0x3B>;
            clocks = <0x3 0x17>;
            phandle = <0x17>;
            legacy-interrupt-controller {
                interrupt-controller;
                #address-cells = <0x0>;
                #interrupt-cells = <0x1>;
                phandle = <0x18>;
            };
        };
        spi@ff0f0000 {
            u-boot,dm-pre-reloc;
            compatible = "xlnx,zynqmp-qspi-1.0";
            status = "okay";
            clock-names = "ref_clk", "pclk";
            interrupts = <0x0 0xF 0x4>;
            interrupt-parent = <0x4>;
            num-cs = <0x1>;
            reg = <0x0 0xFF0F0000 0x0 0x1000 0x0 0xC0000000 0x0 0x8000000>;
            #address-cells = <0x1>;
            #size-cells = <0x0>;
            #stream-id-cells = <0x1>;
            iommus = <0xE 0x873>;
            power-domains = <0xC 0x2D>;
            clocks = <0x3 0x35 0x3 0x1F>;
            is-dual = <0x1>;
            flash@0 {
                compatible = "m25p80", "jedec,spi-nor";
                #address-cells = <0x1>;
                #size-cells = <0x1>;
                reg = <0x0>;
                spi-tx-bus-width = <0x1>;
                spi-rx-bus-width = <0x4>;
                spi-max-frequency = <0x66FF300>;
                partition@qspi-fsbl-uboot {
                    label = "qspi-fsbl-uboot";
                    reg = <0x0 0x100000>;
                };
                partition@qspi-linux {
                    label = "qspi-linux";
                    reg = <0x100000 0x500000>;
                };
                partition@qspi-device-tree {
                    label = "qspi-device-tree";
                    reg = <0x600000 0x20000>;
                };
                partition@qspi-rootfs {
                    label = "qspi-rootfs";
                    reg = <0x620000 0x5E0000>;
                };
            };
        };
        rtc@ffa60000 {
            compatible = "xlnx,zynqmp-rtc";
            status = "okay";
            reg = <0x0 0xFFA60000 0x0 0x100>;
            interrupt-parent = <0x4>;
            interrupts = <0x0 0x1A 0x4 0x0 0x1B 0x4>;
            interrupt-names = "alarm", "sec";
            calibration = <0x8000>;
        };
        zynqmp_phy@fd400000 {
            compatible = "xlnx,zynqmp-psgtr-v1.1";
            status = "okay";
            reg = <0x0 0xFD400000 0x0 0x40000 0x0 0xFD3D0000 0x0 0x1000>;
            reg-names = "serdes", "siou";
            nvmem-cells = <0x19>;
            nvmem-cell-names = "soc_revision";
            resets = <0x1A 0x10 0x1A 0x3B 0x1A 0x3C 0x1A 0x3D 0x1A 0x3E 0x1A 0x3F 0x1A 0x40 0x1A 0x3 0x1A 0x1D 0x1A 0x1E 0x1A 0x1F 0x1A 0x20>;
            reset-names = "sata_rst", "usb0_crst", "usb1_crst", "usb0_hibrst", "usb1_hibrst", "usb0_apbrst", "usb1_apbrst", "dp_rst", "gem0_rst", "gem1_rst", "gem2_rst", "gem3_rst";
            lane0 {
                #phy-cells = <0x4>;
            };
            lane1 {
                #phy-cells = <0x4>;
                phandle = <0x2D>;
            };
            lane2 {
                #phy-cells = <0x4>;
                phandle = <0x2B>;
            };
            lane3 {
                #phy-cells = <0x4>;
                phandle = <0x1B>;
            };
        };
        ahci@fd0c0000 {
            compatible = "ceva,ahci-1v84";
            status = "okay";
            reg = <0x0 0xFD0C0000 0x0 0x2000>;
            interrupt-parent = <0x4>;
            interrupts = <0x0 0x85 0x4>;
            power-domains = <0xC 0x1C>;
            #stream-id-cells = <0x4>;
            clocks = <0x3 0x16>;
            ceva,p0-cominit-params = <0x18401828>;
            ceva,p0-comwake-params = <0x614080E>;
            ceva,p0-burst-params = <0x13084A06>;
            ceva,p0-retry-params = <0x96A43FFC>;
            ceva,p1-cominit-params = <0x18401828>;
            ceva,p1-comwake-params = <0x614080E>;
            ceva,p1-burst-params = <0x13084A06>;
            ceva,p1-retry-params = <0x96A43FFC>;
            phy-names = "sata-phy";
            phys = <0x1B 0x1 0x1 0x1 0x7735940>;
        };
        mmc@ff160000 {
            u-boot,dm-pre-reloc;
            compatible = "xlnx,zynqmp-8.9a", "arasan,sdhci-8.9a";
            status = "disabled";
            interrupt-parent = <0x4>;
            interrupts = <0x0 0x30 0x4>;
            reg = <0x0 0xFF160000 0x0 0x1000>;
            clock-names = "clk_xin", "clk_ahb";
            xlnx,device_id = <0x0>;
            #stream-id-cells = <0x1>;
            iommus = <0xE 0x870>;
            power-domains = <0xC 0x27>;
            nvmem-cells = <0x19>;
            nvmem-cell-names = "soc_revision";
            clocks = <0x3 0x36 0x3 0x1F>;
        };
        mmc@ff170000 {
            u-boot,dm-pre-reloc;
            compatible = "xlnx,zynqmp-8.9a", "arasan,sdhci-8.9a";
            status = "okay";
            interrupt-parent = <0x4>;
            interrupts = <0x0 0x31 0x4>;
            reg = <0x0 0xFF170000 0x0 0x1000>;
            clock-names = "clk_xin", "clk_ahb";
            xlnx,device_id = <0x1>;
            #stream-id-cells = <0x1>;
            iommus = <0xE 0x871>;
            power-domains = <0xC 0x28>;
            nvmem-cells = <0x19>;
            nvmem-cell-names = "soc_revision";
            clocks = <0x3 0x37 0x3 0x1F>;
            pinctrl-names = "default";
            pinctrl-0 = <0x1C>;
            xlnx,mio_bank = <0x1>;
        };
        spi@ff040000 {
            compatible = "cdns,spi-r1p6";
            status = "okay";
            interrupt-parent = <0x4>;
            interrupts = <0x0 0x13 0x4>;
            reg = <0x0 0xFF040000 0x0 0x1000>;
            clock-names = "ref_clk", "pclk";
            #address-cells = <0x1>;
            #size-cells = <0x0>;
            power-domains = <0xC 0x23>;
            clocks = <0x3 0x3A 0x3 0x1F>;
            ad9081@0 {
                #address-cells = <0x1>;
                #size-cells = <0x0>;
                compatible = "adi,ad9081";
                reg = <0x0>;
                spi-max-frequency = <0x4C4B40>;
                clocks = <0x1D 0x2>;
                clock-names = "dev_clk";
                clock-output-names = "rx_sampl_clk", "tx_sampl_clk";
                #clock-cells = <0x1>;
                jesd204-device;
                #jesd204-cells = <0x2>;
                jesd204-top-device = <0x0>;
                jesd204-link-ids = <0x2 0x0>;
                jesd204-inputs = <0x1E 0x0 0x2 0x1F 0x0 0x0>;
                reset-gpios = <0x14 0x85 0x0>;
                sysref-req-gpios = <0x14 0x79 0x0>;
                rx2-enable-gpios = <0x14 0x87 0x0>;
                rx1-enable-gpios = <0x14 0x86 0x0>;
                tx2-enable-gpios = <0x14 0x89 0x0>;
                tx1-enable-gpios = <0x14 0x88 0x0>;
                phandle = <0x33>;
                adi,tx-dacs {
                    #size-cells = <0x0>;
                    #address-cells = <0x1>;
                    adi,dac-frequency-hz = <0x2 0xCB417800>;
                    adi,main-data-paths {
                        #address-cells = <0x1>;
                        #size-cells = <0x0>;
                        adi,interpolation = <0x8>;
                        dac@0 {
                            reg = <0x0>;
                            adi,crossbar-select = <0x20>;
                            adi,nco-frequency-shift-hz = <0x0 0x3B9ACA00>;
                        };
                        dac@1 {
                            reg = <0x1>;
                            adi,crossbar-select = <0x21>;
                            adi,nco-frequency-shift-hz = <0x0 0x4190AB00>;
                        };
                        dac@2 {
                            reg = <0x2>;
                            adi,crossbar-select = <0x22>;
                            adi,nco-frequency-shift-hz = <0x0 0x47868C00>;
                        };
                        dac@3 {
                            reg = <0x3>;
                            adi,crossbar-select = <0x23>;
                            adi,nco-frequency-shift-hz = <0x0 0x4D7C6D00>;
                        };
                    };
                    adi,channelizer-paths {
                        #address-cells = <0x1>;
                        #size-cells = <0x0>;
                        adi,interpolation = <0x6>;
                        channel@0 {
                            reg = <0x0>;
                            adi,gain = <0x800>;
                            adi,nco-frequency-shift-hz = <0x0 0x0>;
                            phandle = <0x20>;
                        };
                        channel@1 {
                            reg = <0x1>;
                            adi,gain = <0x800>;
                            adi,nco-frequency-shift-hz = <0x0 0x0>;
                            phandle = <0x21>;
                        };
                        channel@2 {
                            reg = <0x2>;
                            adi,gain = <0x800>;
                            adi,nco-frequency-shift-hz = <0x0 0x0>;
                            phandle = <0x22>;
                        };
                        channel@3 {
                            reg = <0x3>;
                            adi,gain = <0x800>;
                            adi,nco-frequency-shift-hz = <0x0 0x0>;
                            phandle = <0x23>;
                        };
                    };
                    adi,jesd-links {
                        #size-cells = <0x0>;
                        #address-cells = <0x1>;
                        link@0 {
                            #address-cells = <0x1>;
                            #size-cells = <0x0>;
                            reg = <0x0>;
                            adi,converter-select = <0x20 0x0 0x20 0x1 0x21 0x0 0x21 0x1>;
                            adi,logical-lane-mapping = <0x20707 0x1070703>;
                            adi,link-mode = <0x9>;
                            adi,subclass = <0x1>;
                            adi,version = <0x1>;
                            adi,dual-link = <0x0>;
                            adi,converters-per-device = <0x8>;
                            adi,octets-per-frame = <0x4>;
                            adi,frames-per-multiframe = <0x20>;
                            adi,converter-resolution = <0x10>;
                            adi,bits-per-sample = <0x10>;
                            adi,control-bits-per-sample = <0x0>;
                            adi,lanes-per-device = <0x4>;
                            adi,samples-per-converter-per-frame = <0x1>;
                            adi,high-density = <0x1>;
                        };
                    };
                };
                adi,rx-adcs {
                    #size-cells = <0x0>;
                    #address-cells = <0x1>;
                    adi,adc-frequency-hz = <0x0 0xEE6B2800>;
                    adi,main-data-paths {
                        #address-cells = <0x1>;
                        #size-cells = <0x0>;
                        adc@0 {
                            reg = <0x0>;
                            adi,decimation = <0x4>;
                            adi,nco-frequency-shift-hz = <0x0 0x17D78400>;
                            adi,nco-mode = <0x0>;
                        };
                        adc@1 {
                            reg = <0x1>;
                            adi,decimation = <0x4>;
                            adi,nco-frequency-shift-hz = <0xFFFFFFFF 0xE8287C00>;
                            adi,nco-mode = <0x0>;
                        };
                        adc@2 {
                            reg = <0x2>;
                            adi,decimation = <0x4>;
                            adi,nco-frequency-shift-hz = <0x0 0x5F5E100>;
                            adi,nco-mode = <0x0>;
                        };
                        adc@3 {
                            reg = <0x3>;
                            adi,decimation = <0x4>;
                            adi,nco-frequency-shift-hz = <0x0 0x5F5E100>;
                            adi,nco-mode = <0x0>;
                        };
                    };
                    adi,channelizer-paths {
                        #address-cells = <0x1>;
                        #size-cells = <0x0>;
                        channel@0 {
                            reg = <0x0>;
                            adi,decimation = <0x4>;
                            adi,gain = <0x800>;
                            adi,nco-frequency-shift-hz = <0x0 0x0>;
                            phandle = <0x24>;
                        };
                        channel@1 {
                            reg = <0x1>;
                            adi,decimation = <0x4>;
                            adi,gain = <0x800>;
                            adi,nco-frequency-shift-hz = <0x0 0x0>;
                            phandle = <0x25>;
                        };
                        channel@4 {
                            reg = <0x4>;
                            adi,decimation = <0x4>;
                            adi,gain = <0x800>;
                            adi,nco-frequency-shift-hz = <0x0 0x0>;
                            phandle = <0x26>;
                        };
                        channel@5 {
                            reg = <0x5>;
                            adi,decimation = <0x4>;
                            adi,gain = <0x800>;
                            adi,nco-frequency-shift-hz = <0x0 0x0>;
                            phandle = <0x27>;
                        };
                    };
                    adi,jesd-links {
                        #size-cells = <0x0>;
                        #address-cells = <0x1>;
                        link@0 {
                            reg = <0x0>;
                            adi,converter-select = <0x24 0x0 0x24 0x1 0x25 0x0 0x25 0x1 0x26 0x0 0x26 0x1 0x27 0x0 0x27 0x1>;
                            adi,logical-lane-mapping = <0x2000707 0x7070301>;
                            adi,link-mode = <0xA>;
                            adi,subclass = <0x1>;
                            adi,version = <0x1>;
                            adi,dual-link = <0x0>;
                            adi,converters-per-device = <0x8>;
                            adi,octets-per-frame = <0x4>;
                            adi,frames-per-multiframe = <0x20>;
                            adi,converter-resolution = <0x10>;
                            adi,bits-per-sample = <0x10>;
                            adi,control-bits-per-sample = <0x0>;
                            adi,lanes-per-device = <0x4>;
                            adi,samples-per-converter-per-frame = <0x1>;
                            adi,high-density = <0x1>;
                        };
                    };
                };
            };
        };
        spi@ff050000 {
            compatible = "cdns,spi-r1p6";
            status = "okay";
            interrupt-parent = <0x4>;
            interrupts = <0x0 0x14 0x4>;
            reg = <0x0 0xFF050000 0x0 0x1000>;
            clock-names = "ref_clk", "pclk";
            #address-cells = <0x1>;
            #size-cells = <0x0>;
            power-domains = <0xC 0x24>;
            clocks = <0x3 0x3B 0x3 0x1F>;
            hmc7044@0 {
                #address-cells = <0x1>;
                #size-cells = <0x0>;
                #clock-cells = <0x1>;
                compatible = "adi,hmc7044";
                reg = <0x0>;
                spi-max-frequency = <0xF4240>;
                jesd204-device;
                #jesd204-cells = <0x2>;
                jesd204-sysref-provider;
                adi,jesd204-max-sysref-frequency-hz = <0x1E8480>;
                adi,pll1-clkin-frequencies = <0x5F5E100 0x989680 0x0 0x0>;
                adi,vcxo-frequency = <0x5F5E100>;
                adi,pll1-loop-bandwidth-hz = <0xC8>;
                adi,pll2-output-frequency = <0xB2D05E00>;
                adi,sysref-timer-divider = <0x400>;
                adi,pulse-generator-mode = <0x0>;
                adi,clkin0-buffer-mode = <0x7>;
                adi,clkin1-buffer-mode = <0x7>;
                adi,oscin-buffer-mode = <0x15>;
                adi,gpi-controls = <0x0 0x0 0x0 0x0>;
                adi,gpo-controls = <0x37 0x33 0x0 0x0>;
                clock-output-names = "hmc7044_out0", "hmc7044_out1", "hmc7044_out2", "hmc7044_out3", "hmc7044_out4", "hmc7044_out5", "hmc7044_out6", "hmc7044_out7", "hmc7044_out8", "hmc7044_out9", "hmc7044_out10", "hmc7044_out11", "hmc7044_out12", "hmc7044_out13";
                phandle = <0x1D>;
                channel@0 {
                    reg = <0x0>;
                    adi,extended-name = "CORE_CLK_RX";
                    adi,divider = <0xC>;
                    adi,driver-mode = <0x2>;
                };
                channel@2 {
                    reg = <0x2>;
                    adi,extended-name = "DEV_REFCLK";
                    adi,divider = <0xC>;
                    adi,driver-mode = <0x2>;
                };
                channel@3 {
                    reg = <0x3>;
                    adi,extended-name = "DEV_SYSREF";
                    adi,divider = <0x600>;
                    adi,driver-mode = <0x2>;
                    adi,jesd204-sysref-chan;
                };
                channel@6 {
                    reg = <0x6>;
                    adi,extended-name = "CORE_CLK_TX";
                    adi,divider = <0xC>;
                    adi,driver-mode = <0x2>;
                };
                channel@8 {
                    reg = <0x8>;
                    adi,extended-name = "FPGA_REFCLK1";
                    adi,divider = <0x6>;
                    adi,driver-mode = <0x2>;
                };
                channel@10 {
                    reg = <0xA>;
                    adi,extended-name = "CORE_CLK_RX_ALT";
                    adi,divider = <0xC>;
                    adi,driver-mode = <0x2>;
                };
                channel@12 {
                    reg = <0xC>;
                    adi,extended-name = "FPGA_REFCLK2";
                    adi,divider = <0x6>;
                    adi,driver-mode = <0x2>;
                };
                channel@13 {
                    reg = <0xD>;
                    adi,extended-name = "FPGA_SYSREF";
                    adi,divider = <0x600>;
                    adi,driver-mode = <0x2>;
                    adi,jesd204-sysref-chan;
                };
            };
        };
        timer@ff110000 {
            compatible = "cdns,ttc";
            status = "disabled";
            interrupt-parent = <0x4>;
            interrupts = <0x0 0x24 0x4 0x0 0x25 0x4 0x0 0x26 0x4>;
            reg = <0x0 0xFF110000 0x0 0x1000>;
            timer-width = <0x20>;
            power-domains = <0xC 0x18>;
            clocks = <0x3 0x1F>;
        };
        timer@ff120000 {
            compatible = "cdns,ttc";
            status = "disabled";
            interrupt-parent = <0x4>;
            interrupts = <0x0 0x27 0x4 0x0 0x28 0x4 0x0 0x29 0x4>;
            reg = <0x0 0xFF120000 0x0 0x1000>;
            timer-width = <0x20>;
            power-domains = <0xC 0x19>;
            clocks = <0x3 0x1F>;
        };
        timer@ff130000 {
            compatible = "cdns,ttc";
            status = "disabled";
            interrupt-parent = <0x4>;
            interrupts = <0x0 0x2A 0x4 0x0 0x2B 0x4 0x0 0x2C 0x4>;
            reg = <0x0 0xFF130000 0x0 0x1000>;
            timer-width = <0x20>;
            power-domains = <0xC 0x1A>;
            clocks = <0x3 0x1F>;
        };
        timer@ff140000 {
            compatible = "cdns,ttc";
            status = "disabled";
            interrupt-parent = <0x4>;
            interrupts = <0x0 0x2D 0x4 0x0 0x2E 0x4 0x0 0x2F 0x4>;
            reg = <0x0 0xFF140000 0x0 0x1000>;
            timer-width = <0x20>;
            power-domains = <0xC 0x1B>;
            clocks = <0x3 0x1F>;
        };
        serial@ff000000 {
            u-boot,dm-pre-reloc;
            compatible = "cdns,uart-r1p12", "xlnx,xuartps";
            status = "okay";
            interrupt-parent = <0x4>;
            interrupts = <0x0 0x15 0x4>;
            reg = <0x0 0xFF000000 0x0 0x1000>;
            clock-names = "uart_clk", "pclk";
            power-domains = <0xC 0x21>;
            clocks = <0x3 0x38 0x3 0x1F>;
            pinctrl-names = "default";
            pinctrl-0 = <0x28>;
        };
        serial@ff010000 {
            u-boot,dm-pre-reloc;
            compatible = "cdns,uart-r1p12", "xlnx,xuartps";
            status = "okay";
            interrupt-parent = <0x4>;
            interrupts = <0x0 0x16 0x4>;
            reg = <0x0 0xFF010000 0x0 0x1000>;
            clock-names = "uart_clk", "pclk";
            power-domains = <0xC 0x22>;
            clocks = <0x3 0x39 0x3 0x1F>;
            pinctrl-names = "default";
            pinctrl-0 = <0x29>;
        };
        usb0@ff9d0000 {
            #address-cells = <0x2>;
            #size-cells = <0x2>;
            status = "okay";
            compatible = "xlnx,zynqmp-dwc3";
            reg = <0x0 0xFF9D0000 0x0 0x100>;
            clock-names = "bus_clk", "ref_clk";
            power-domains = <0xC 0x16>;
            ranges;
            nvmem-cells = <0x19>;
            nvmem-cell-names = "soc_revision";
            clocks = <0x3 0x20 0x3 0x22>;
            pinctrl-names = "default";
            pinctrl-0 = <0x2A>;
            dwc3@fe200000 {
                compatible = "snps,dwc3";
                status = "okay";
                reg = <0x0 0xFE200000 0x0 0x40000>;
                interrupt-parent = <0x4>;
                interrupt-names = "dwc_usb3", "otg", "hiber";
                interrupts = <0x0 0x41 0x4 0x0 0x45 0x4 0x0 0x4B 0x4>;
                #stream-id-cells = <0x1>;
                iommus = <0xE 0x860>;
                snps,quirk-frame-length-adjustment = <0x20>;
                snps,refclk_fladj;
                snps,enable_guctl1_resume_quirk;
                snps,enable_guctl1_ipd_quirk;
                snps,xhci-stream-quirk;
                dr_mode = "host";
                snps,usb3_lpm_capable;
                phy-names = "usb3-phy";
                phys = <0x2B 0x4 0x0 0x2 0x18CBA80>;
                maximum-speed = "super-speed";
            };
        };
        usb1@ff9e0000 {
            #address-cells = <0x2>;
            #size-cells = <0x2>;
            status = "disabled";
            compatible = "xlnx,zynqmp-dwc3";
            reg = <0x0 0xFF9E0000 0x0 0x100>;
            clock-names = "bus_clk", "ref_clk";
            power-domains = <0xC 0x17>;
            ranges;
            nvmem-cells = <0x19>;
            nvmem-cell-names = "soc_revision";
            clocks = <0x3 0x21 0x3 0x22>;
            dwc3@fe300000 {
                compatible = "snps,dwc3";
                status = "disabled";
                reg = <0x0 0xFE300000 0x0 0x40000>;
                interrupt-parent = <0x4>;
                interrupt-names = "dwc_usb3", "otg", "hiber";
                interrupts = <0x0 0x46 0x4 0x0 0x4A 0x4 0x0 0x4C 0x4>;
                #stream-id-cells = <0x1>;
                iommus = <0xE 0x861>;
                snps,quirk-frame-length-adjustment = <0x20>;
                snps,refclk_fladj;
                snps,enable_guctl1_resume_quirk;
                snps,enable_guctl1_ipd_quirk;
                snps,xhci-stream-quirk;
            };
        };
        watchdog@fd4d0000 {
            compatible = "cdns,wdt-r1p2";
            status = "okay";
            interrupt-parent = <0x4>;
            interrupts = <0x0 0x71 0x1>;
            reg = <0x0 0xFD4D0000 0x0 0x1000>;
            timeout-sec = <0x3C>;
            reset-on-timeout;
            clocks = <0x3 0x4B>;
        };
        watchdog@ff150000 {
            compatible = "cdns,wdt-r1p2";
            status = "disabled";
            interrupt-parent = <0x4>;
            interrupts = <0x0 0x34 0x1>;
            reg = <0x0 0xFF150000 0x0 0x1000>;
            timeout-sec = <0xA>;
            clocks = <0x3 0x70>;
        };
        ams@ffa50000 {
            compatible = "xlnx,zynqmp-ams";
            status = "okay";
            interrupt-parent = <0x4>;
            interrupts = <0x0 0x38 0x4>;
            interrupt-names = "ams-irq";
            reg = <0x0 0xFFA50000 0x0 0x800>;
            reg-names = "ams-base";
            #address-cells = <0x2>;
            #size-cells = <0x2>;
            #io-channel-cells = <0x1>;
            ranges;
            clocks = <0x3 0x46>;
            ams_ps@ffa50800 {
                compatible = "xlnx,zynqmp-ams-ps";
                status = "okay";
                reg = <0x0 0xFFA50800 0x0 0x400>;
            };
            ams_pl@ffa50c00 {
                compatible = "xlnx,zynqmp-ams-pl";
                status = "okay";
                reg = <0x0 0xFFA50C00 0x0 0x400>;
            };
        };
        dma@fd4c0000 {
            compatible = "xlnx,dpdma";
            status = "okay";
            reg = <0x0 0xFD4C0000 0x0 0x1000>;
            interrupts = <0x0 0x7A 0x4>;
            interrupt-parent = <0x4>;
            clock-names = "axi_clk";
            power-domains = <0xC 0x29>;
            dma-channels = <0x6>;
            #dma-cells = <0x1>;
            clocks = <0x3 0x14>;
            phandle = <0x2E>;
            dma-video0channel {
                compatible = "xlnx,video0";
            };
            dma-video1channel {
                compatible = "xlnx,video1";
            };
            dma-video2channel {
                compatible = "xlnx,video2";
            };
            dma-graphicschannel {
                compatible = "xlnx,graphics";
            };
            dma-audio0channel {
                compatible = "xlnx,audio0";
            };
            dma-audio1channel {
                compatible = "xlnx,audio1";
            };
        };
        zynqmp-display@fd4a0000 {
            compatible = "xlnx,zynqmp-dpsub-1.7";
            status = "okay";
            reg = <0x0 0xFD4A0000 0x0 0x1000 0x0 0xFD4AA000 0x0 0x1000 0x0 0xFD4AB000 0x0 0x1000 0x0 0xFD4AC000 0x0 0x1000>;
            reg-names = "dp", "blend", "av_buf", "aud";
            interrupts = <0x0 0x77 0x4>;
            interrupt-parent = <0x4>;
            clock-names = "dp_apb_clk", "dp_aud_clk", "dp_vtc_pixel_clk_in";
            power-domains = <0xC 0x29>;
            clocks = <0x2C 0x3 0x11 0x3 0x10>;
            phy-names = "dp-phy0";
            phys = <0x2D 0x6 0x0 0x3 0x19BFCC0>;
            vid-layer {
                dma-names = "vid0", "vid1", "vid2";
                dmas = <0x2E 0x0 0x2E 0x1 0x2E 0x2>;
            };
            gfx-layer {
                dma-names = "gfx0";
                dmas = <0x2E 0x3>;
            };
            i2c-bus {
            };
            zynqmp_dp_snd_codec0 {
                compatible = "xlnx,dp-snd-codec";
                clock-names = "aud_clk";
                clocks = <0x3 0x11>;
                status = "okay";
                phandle = <0x31>;
            };
            zynqmp_dp_snd_pcm0 {
                compatible = "xlnx,dp-snd-pcm";
                dmas = <0x2E 0x4>;
                dma-names = "tx";
                status = "okay";
                phandle = <0x2F>;
            };
            zynqmp_dp_snd_pcm1 {
                compatible = "xlnx,dp-snd-pcm";
                dmas = <0x2E 0x5>;
                dma-names = "tx";
                status = "okay";
                phandle = <0x30>;
            };
            zynqmp_dp_snd_card {
                compatible = "xlnx,dp-snd-card";
                xlnx,dp-snd-pcm = <0x2F 0x30>;
                xlnx,dp-snd-codec = <0x31>;
                status = "okay";
            };
        };
    };
    fclk0 {
        status = "okay";
        compatible = "xlnx,fclk";
        clocks = <0x3 0x47>;
    };
    fclk1 {
        status = "okay";
        compatible = "xlnx,fclk";
        clocks = <0x3 0x48>;
    };
    fclk2 {
        status = "okay";
        compatible = "xlnx,fclk";
        clocks = <0x3 0x49>;
    };
    fclk3 {
        status = "okay";
        compatible = "xlnx,fclk";
        clocks = <0x3 0x4A>;
    };
    pss_ref_clk {
        u-boot,dm-pre-reloc;
        compatible = "fixed-clock";
        #clock-cells = <0x0>;
        clock-frequency = <0x1FCA055>;
        phandle = <0x6>;
    };
    video_clk {
        u-boot,dm-pre-reloc;
        compatible = "fixed-clock";
        #clock-cells = <0x0>;
        clock-frequency = <0x19BFCC0>;
        phandle = <0x7>;
    };
    pss_alt_ref_clk {
        u-boot,dm-pre-reloc;
        compatible = "fixed-clock";
        #clock-cells = <0x0>;
        clock-frequency = <0x0>;
        phandle = <0x8>;
    };
    gt_crx_ref_clk {
        u-boot,dm-pre-reloc;
        compatible = "fixed-clock";
        #clock-cells = <0x0>;
        clock-frequency = <0x66FF300>;
        phandle = <0xA>;
    };
    aux_ref_clk {
        u-boot,dm-pre-reloc;
        compatible = "fixed-clock";
        #clock-cells = <0x0>;
        clock-frequency = <0x19BFCC0>;
        phandle = <0x9>;
    };
    dp_aclk {
        compatible = "fixed-clock";
        #clock-cells = <0x0>;
        clock-frequency = <0x5F5E100>;
        clock-accuracy = <0x64>;
        phandle = <0x2C>;
    };
    aliases {
        ethernet0 = "/amba/ethernet@ff0e0000";
        gpio0 = "/amba/gpio@ff0a0000";
        i2c0 = "/amba/i2c@ff020000";
        i2c1 = "/amba/i2c@ff030000";
        mmc0 = "/amba/mmc@ff170000";
        rtc0 = "/amba/rtc@ffa60000";
        serial0 = "/amba/serial@ff000000";
        serial1 = "/amba/serial@ff010000";
        serial2 = "/dcc";
        spi0 = "/amba/spi@ff0f0000";
        usb0 = "/amba/usb0@ff9d0000";
    };
    chosen {
        bootargs = "earlycon";
        stdout-path = "serial0:115200n8";
        xlnx,eeprom = "/amba/i2c@ff030000/i2c-mux@74/i2c@0/eeprom@54";
    };
    memory@0 {
        device_type = "memory";
        reg = <0x0 0x0 0x0 0x80000000 0x8 0x0 0x0 0x80000000>;
    };
    gpio-keys {
        compatible = "gpio-keys";
        autorepeat;
        sw19 {
            label = "sw19";
            gpios = <0x14 0x16 0x0>;
            linux,code = <0x6C>;
            gpio-key,wakeup;
            autorepeat;
        };
    };
    leds {
        compatible = "gpio-leds";
        heartbeat_led {
            label = "heartbeat";
            gpios = <0x14 0x17 0x0>;
            linux,default-trigger = "heartbeat";
        };
    };
    fpga-axi@0 {
        interrupt-parent = <0x4>;
        compatible = "simple-bus";
        #address-cells = <0x1>;
        #size-cells = <0x1>;
        ranges = <0x0 0x0 0x0 0xFFFFFFFF>;
        dma@9c420000 {
            compatible = "adi,axi-dmac-1.00.a";
            reg = <0x9C420000 0x10000>;
            #dma-cells = <0x1>;
            #clock-cells = <0x0>;
            interrupts = <0x0 0x6D 0x4>;
            clocks = <0x3 0x49>;
            phandle = <0x32>;
        };
        dma@9c430000 {
            compatible = "adi,axi-dmac-1.00.a";
            reg = <0x9C430000 0x10000>;
            #dma-cells = <0x1>;
            #clock-cells = <0x0>;
            interrupts = <0x0 0x6C 0x4>;
            clocks = <0x3 0x49>;
            phandle = <0x35>;
        };
        axi-ad9081-rx-hpc@84a10000 {
            compatible = "adi,axi-ad9081-rx-1.0";
            reg = <0x84A10000 0x8000>;
            dmas = <0x32 0x0>;
            dma-names = "rx";
            spibus-connected = <0x33>;
            jesd204-device;
            #jesd204-cells = <0x2>;
            jesd204-inputs = <0x34 0x0 0x2>;
            phandle = <0x1E>;
        };
        axi-ad9081-tx-hpc@84b10000 {
            compatible = "adi,axi-ad9081-tx-1.0";
            reg = <0x84B10000 0x4000>;
            dmas = <0x35 0x0>;
            dma-names = "tx";
            clocks = <0x33 0x1>;
            clock-names = "sampl_clk";
            spibus-connected = <0x33>;
            jesd204-device;
            #jesd204-cells = <0x2>;
            jesd204-inputs = <0x36 0x0 0x0>;
            plddrbypass-gpios = <0x14 0x8A 0x0>;
            phandle = <0x1F>;
        };
        axi-jesd204-rx@84a90000 {
            compatible = "adi,axi-jesd204-rx-1.0";
            reg = <0x84A90000 0x1000>;
            interrupts = <0x0 0x6B 0x4>;
            clocks = <0x3 0x47 0x1D 0xA 0x37 0x0>;
            clock-names = "s_axi_aclk", "device_clk", "lane_clk";
            #clock-cells = <0x0>;
            clock-output-names = "jesd_rx_lane_clk";
            jesd204-device;
            #jesd204-cells = <0x2>;
            jesd204-inputs = <0x37 0x0 0x2>;
            phandle = <0x34>;
        };
        axi-jesd204-tx@84b90000 {
            compatible = "adi,axi-jesd204-tx-1.0";
            reg = <0x84B90000 0x1000>;
            interrupts = <0x0 0x6A 0x4>;
            clocks = <0x3 0x47 0x1D 0x6 0x38 0x0>;
            clock-names = "s_axi_aclk", "device_clk", "lane_clk";
            #clock-cells = <0x0>;
            clock-output-names = "jesd_tx_lane_clk";
            jesd204-device;
            #jesd204-cells = <0x2>;
            jesd204-inputs = <0x38 0x0 0x0>;
            phandle = <0x36>;
        };
        axi-adxcvr-rx@84a60000 {
            #address-cells = <0x1>;
            #size-cells = <0x0>;
            compatible = "adi,axi-adxcvr-1.0";
            reg = <0x84A60000 0x1000>;
            clocks = <0x1D 0xC>;
            clock-names = "conv";
            #clock-cells = <0x1>;
            clock-output-names = "rx_gt_clk", "rx_out_clk";
            adi,sys-clk-select = <0x0>;
            adi,out-clk-select = <0x4>;
            adi,use-lpm-enable;
            jesd204-device;
            #jesd204-cells = <0x2>;
            jesd204-inputs = <0x1D 0x0 0x2>;
            phandle = <0x37>;
        };
        axi-adxcvr-tx@84b60000 {
            #address-cells = <0x1>;
            #size-cells = <0x0>;
            compatible = "adi,axi-adxcvr-1.0";
            reg = <0x84B60000 0x1000>;
            clocks = <0x1D 0xC>;
            clock-names = "conv";
            #clock-cells = <0x1>;
            clock-output-names = "tx_gt_clk", "tx_out_clk";
            adi,sys-clk-select = <0x3>;
            adi,out-clk-select = <0x4>;
            jesd204-device;
            #jesd204-cells = <0x2>;
            jesd204-inputs = <0x1D 0x0 0x0>;
            phandle = <0x38>;
        };
        axi-sysid-0@85000000 {
            compatible = "adi,axi-sysid-1.00.a";
            reg = <0x85000000 0x10000>;
        };
    };
};
